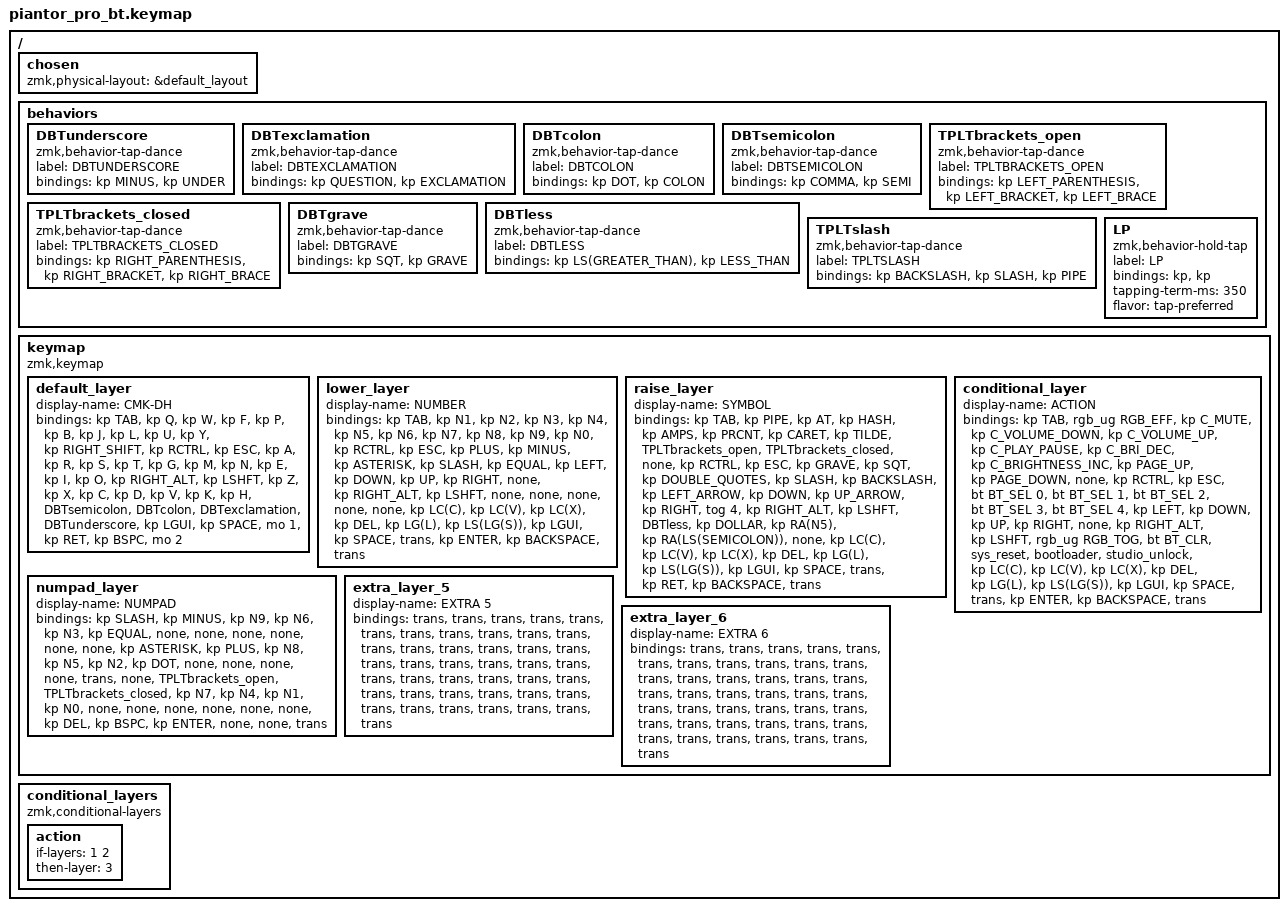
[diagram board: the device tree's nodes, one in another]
/*
 * Copyright (c) 2020 The ZMK Contributors
 *
 * SPDX-License-Identifier: MIT
 */

#include <behaviors.dtsi>
#include <dt-bindings/zmk/bt.h>
#include <dt-bindings/zmk/keys.h>
#include <dt-bindings/zmk/rgb.h>

/ {
    chosen { zmk,physical-layout = &default_layout; };
};

/ {
    behaviors {
        DBTunderscore: DBTunderscore {
            compatible = "zmk,behavior-tap-dance";
            label = "DBTUNDERSCORE";
            #binding-cells = <0>;
            bindings = <&kp MINUS>, <&kp UNDER>;
        };

        DBTexclamation: DBTexclamation {
            compatible = "zmk,behavior-tap-dance";
            label = "DBTEXCLAMATION";
            #binding-cells = <0>;
            bindings = <&kp QUESTION>, <&kp EXCLAMATION>;
        };

        DBTcolon: DBTcolon {
            compatible = "zmk,behavior-tap-dance";
            label = "DBTCOLON";
            #binding-cells = <0>;
            bindings = <&kp DOT>, <&kp COLON>;
        };

        DBTsemicolon: DBTsemicolon {
            compatible = "zmk,behavior-tap-dance";
            label = "DBTSEMICOLON";
            #binding-cells = <0>;
            bindings = <&kp COMMA>, <&kp SEMI>;
        };

        TPLTbrackets_open: TPLTbrackets_open {
            compatible = "zmk,behavior-tap-dance";
            label = "TPLTBRACKETS_OPEN";
            #binding-cells = <0>;
            bindings =
                <&kp LEFT_PARENTHESIS>,
                <&kp LEFT_BRACKET>,
                <&kp LEFT_BRACE>;
        };

        TPLTbrackets_closed: TPLTbrackets_closed {
            compatible = "zmk,behavior-tap-dance";
            label = "TPLTBRACKETS_CLOSED";
            #binding-cells = <0>;
            bindings =
                <&kp RIGHT_PARENTHESIS>,
                <&kp RIGHT_BRACKET>,
                <&kp RIGHT_BRACE>;
        };

        DBTgrave: DBTgrave {
            compatible = "zmk,behavior-tap-dance";
            label = "DBTGRAVE";
            #binding-cells = <0>;
            bindings = <&kp SQT>, <&kp GRAVE>;
        };

        DBTless: DBTless {
            compatible = "zmk,behavior-tap-dance";
            label = "DBTLESS";
            #binding-cells = <0>;
            bindings = <&kp LS(GREATER_THAN)>, <&kp LESS_THAN>;
        };

        TPLTslash: TPLTslash {
            compatible = "zmk,behavior-tap-dance";
            label = "TPLTSLASH";
            #binding-cells = <0>;
            bindings = <&kp BACKSLASH>, <&kp SLASH>, <&kp PIPE>;
        };

        LP: LP {
            compatible = "zmk,behavior-hold-tap";
            label = "LP";
            bindings = <&kp>, <&kp>;

            #binding-cells = <2>;
            tapping-term-ms = <350>;
            flavor = "tap-preferred";
        };
    };

    keymap {
        compatible = "zmk,keymap";

        default_layer {
            display-name = "CMK-DH";

            // --------------------------------------------------------------------------------
            // |  TAB |  Q  |  W  |  E  |  R  |  T  |  Y  |  U   |  I  |  O  |  P  | BSPC |
            // | CTRL |  A  |  S  |  D  |  F  |  G  |  H  |  J   |  K  |  L  |  ;  |  '   |
            // | SHFT |  Z  |  X  |  C  |  V  |  B  |  N  |  M   |  ,  |  .  |  /  | ESC  |
            //                    | GUI | LWR | SPC | ENT | RSE  | ALT |

            bindings = <
&kp TAB  &kp Q  &kp W  &kp F  &kp P  &kp B  &kp J  &kp L  &kp U  &kp Y  &kp RIGHT_SHIFT  &kp RCTRL  &kp ESC  &kp A  &kp R  &kp S  &kp T  &kp G  &kp M  &kp N  &kp E  &kp I  &kp O  &kp RIGHT_ALT  &kp LSHFT  &kp Z  &kp X  &kp C  &kp D  &kp V  &kp K  &kp H  &DBTsemicolon  &DBTcolon  &DBTexclamation  &DBTunderscore  &kp LGUI  &kp SPACE  &mo 1  &kp RET  &kp BSPC  &mo 2
            >;
        };

        lower_layer {
            display-name = "NUMBER";

            // -----------------------------------------------------------------------------------------
            // |  TAB |  1  |  2  |  3  |  4  |  5    |  6  |  7  |  8  |  9  |  0  | BSPC |
            // | CTRL | BT1 | BT2 | BT3 | BT4 | BT5   | LFT | DWN |  UP | RGT |     |      |
            // | SHFT | BTCR| RGB | RST | BOOT| Unlock|     |     |     |     |     |      |
            //                    | GUI |     | SPC   | ENT |     | ALT |

            bindings = <
&kp TAB  &kp N1  &kp N2  &kp N3  &kp N4  &kp N5  &kp N6  &kp N7  &kp N8  &kp N9  &kp N0  &kp RCTRL  &kp ESC  &kp PLUS  &kp MINUS  &kp ASTERISK  &kp SLASH  &kp EQUAL  &kp LEFT  &kp DOWN  &kp UP  &kp RIGHT  &none  &kp RIGHT_ALT  &kp LSHFT  &none  &none  &none  &none  &none  &kp LC(C)  &kp LC(V)  &kp LC(X)  &kp DEL  &kp LG(L)  &kp LS(LG(S))  &kp LGUI  &kp SPACE  &trans  &kp ENTER  &kp BACKSPACE  &trans
            >;
        };

        raise_layer {
            display-name = "SYMBOL";

            // -----------------------------------------------------------------------------------------
            // |  TAB |  !  |  @  |  #  |  $  |  %  |  ^  |  &  |  *  |  (  |  )  | BSPC |
            // | CTRL |     |     |     |     |     |  -  |  =  |  [  |  ]  |  \  |  `   |
            // | SHFT |     |     |     |     |     |  _  |  +  |  {  |  }  | "|" |  ~   |
            //                    | GUI |     | SPC | ENT |     | ALT |

            bindings = <
&kp TAB  &kp PIPE  &kp AT  &kp HASH  &kp AMPS  &kp PRCNT  &kp CARET  &kp TILDE  &TPLTbrackets_open  &TPLTbrackets_closed  &none  &kp RCTRL  &kp ESC  &kp GRAVE  &kp SQT  &kp DOUBLE_QUOTES  &kp SLASH  &kp BACKSLASH  &kp LEFT_ARROW  &kp DOWN  &kp UP_ARROW  &kp RIGHT  &tog 4  &kp RIGHT_ALT  &kp LSHFT  &DBTless  &kp DOLLAR  &kp RA(N5)  &kp RA(LS(SEMICOLON))  &none  &kp LC(C)  &kp LC(V)  &kp LC(X)  &kp DEL  &kp LG(L)  &kp LS(LG(S))  &kp LGUI  &kp SPACE  &trans  &kp RET  &kp BACKSPACE  &trans
            >;
        };

        conditional_layer {
            display-name = "ACTION";
            bindings = <
&kp TAB  &rgb_ug RGB_EFF  &kp C_MUTE  &kp C_VOLUME_DOWN  &kp C_VOLUME_UP  &kp C_PLAY_PAUSE  &kp C_BRI_DEC  &kp C_BRIGHTNESS_INC  &kp PAGE_UP  &kp PAGE_DOWN  &none  &kp RCTRL  &kp ESC  &bt BT_SEL 0  &bt BT_SEL 1  &bt BT_SEL 2  &bt BT_SEL 3  &bt BT_SEL 4  &kp LEFT  &kp DOWN  &kp UP  &kp RIGHT  &none  &kp RIGHT_ALT  &kp LSHFT  &rgb_ug RGB_TOG  &bt BT_CLR  &sys_reset  &bootloader  &studio_unlock  &kp LC(C)  &kp LC(V)  &kp LC(X)  &kp DEL  &kp LG(L)  &kp LS(LG(S))  &kp LGUI  &kp SPACE  &trans  &kp ENTER  &kp BACKSPACE  &trans
            >;
        };

        numpad_layer {
            display-name = "NUMPAD";
            bindings = <
&kp SLASH  &kp MINUS  &kp N9  &kp N6  &kp N3  &kp EQUAL  &none  &none  &none  &none  &none  &none  &kp ASTERISK  &kp PLUS  &kp N8  &kp N5  &kp N2  &kp DOT  &none  &none  &none  &none  &trans  &none  &TPLTbrackets_open  &TPLTbrackets_closed  &kp N7  &kp N4  &kp N1  &kp N0  &none  &none  &none  &none  &none  &none  &kp DEL  &kp BSPC  &kp ENTER  &none  &none  &trans
            >;
        };

        extra_layer_5 {
            display-name = "EXTRA 5";
            bindings = <
&trans  &trans  &trans  &trans  &trans  &trans  &trans  &trans  &trans  &trans  &trans  &trans  &trans  &trans  &trans  &trans  &trans  &trans  &trans  &trans  &trans  &trans  &trans  &trans  &trans  &trans  &trans  &trans  &trans  &trans  &trans  &trans  &trans  &trans  &trans  &trans  &trans  &trans  &trans  &trans  &trans  &trans
            >;
        };

        extra_layer_6 {
            display-name = "EXTRA 6";
            bindings = <
&trans  &trans  &trans  &trans  &trans  &trans  &trans  &trans  &trans  &trans  &trans  &trans  &trans  &trans  &trans  &trans  &trans  &trans  &trans  &trans  &trans  &trans  &trans  &trans  &trans  &trans  &trans  &trans  &trans  &trans  &trans  &trans  &trans  &trans  &trans  &trans  &trans  &trans  &trans  &trans  &trans  &trans
            >;
        };
    };

    conditional_layers {
        compatible = "zmk,conditional-layers";

        action {
            if-layers = <1 2>;
            then-layer = <3>;
        };
    };
};
